# PIC32MX254F128D register map
Vendor: Microchip
Registers are 32-bit, read-write, reset 0x0 unless marked. A register's access mark holds for its fields unless they carry their own. Addresses are absolute, and some are shared; only a register's first bit layout is shown; [hi:lo] are bit positions; {n}, {i} and the like mark numbered series.

## CMP3
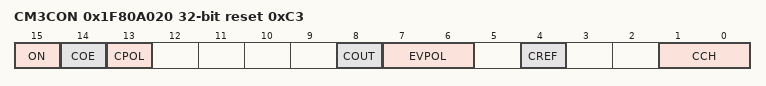
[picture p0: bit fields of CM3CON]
0x1F80A020 CM3CON reset 0xC3
  [15] ON, [14] COE, [13] CPOL, [8] COUT, [7:6] EVPOL, [4] CREF, [1:0] CCH

## cmp_control_pb
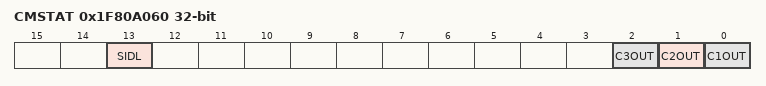
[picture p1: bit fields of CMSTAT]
0x1F80A060 CMSTAT reset not defined — (power-on value ------------------------00---x00)
  [13] SIDL, [2] C3OUT, [1] C2OUT ro, [0] C1OUT ro

## CTMU
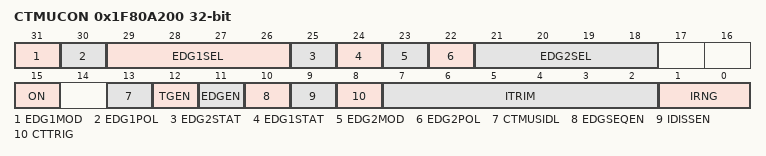
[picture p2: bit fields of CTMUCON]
0x1F80A200 CTMUCON
  [31] EDG1MOD, [30] EDG1POL, [29:26] EDG1SEL, [25] EDG2STAT, [24] EDG1STAT, [23] EDG2MOD, [22] EDG2POL, [21:18] EDG2SEL, [15] ON, [13] CTMUSIDL, [12] TGEN, [11] EDGEN, [10] EDGSEQEN, [9] IDISSEN, [8] CTTRIG, [7:2] ITRIM, [1:0] IRNG

## CRU
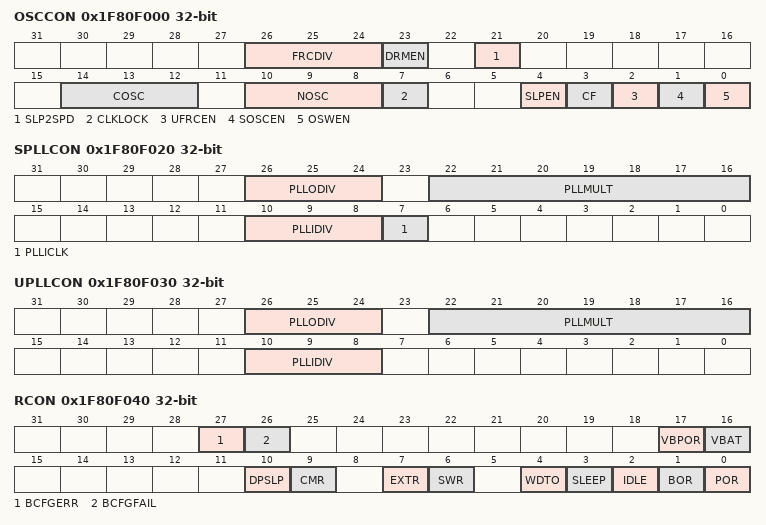
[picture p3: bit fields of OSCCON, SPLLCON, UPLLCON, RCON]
0x1F80F000 OSCCON reset not defined — (power-on value -----0000-x------000-xxx0--000x0)
  [26:24] FRCDIV, [23] DRMEN, [21] SLP2SPD, [14:12] COSC ro, [10:8] NOSC, [7] CLKLOCK, [4] SLPEN, [3] CF, [2] UFRCEN, [1] SOSCEN, [0] OSWEN
0x1F80F010 OSCTUN
  [5:0] TUN
0x1F80F020 SPLLCON reset not defined — (power-on value -----001-xxxxxxx-----xxx0-------)
  [26:24] PLLODIV, [22:16] PLLMULT, [10:8] PLLIDIV, [7] PLLICLK
0x1F80F030 UPLLCON reset not defined — (power-on value -----001-xxxxxxx-----001--------)
  [26:24] PLLODIV, [22:16] PLLMULT, [10:8] PLLIDIV
0x1F80F040 RCON reset not defined — (power-on value ----00---------------x0-00-00011)
  [27] BCFGERR, [26] BCFGFAIL, [17] VBPOR, [16] VBAT, [10] DPSLP, [9] CMR, [7] EXTR, [6] SWR, [4] WDTO, [3] SLEEP, [2] IDLE, [1] BOR, [0] POR
0x1F80F050 RSWRST wo
  [0] SWRST
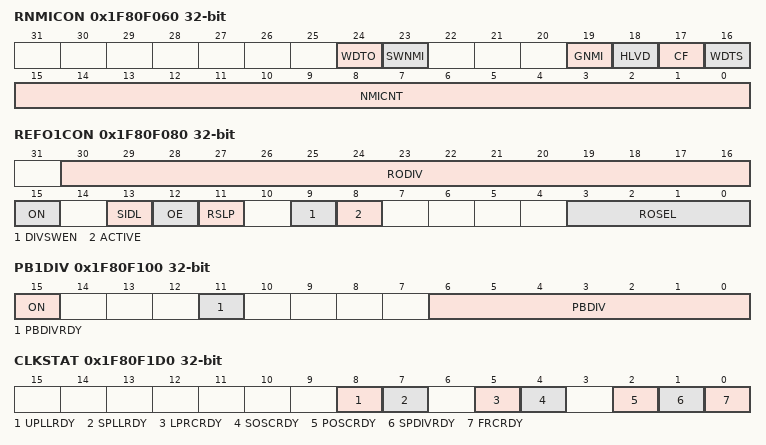
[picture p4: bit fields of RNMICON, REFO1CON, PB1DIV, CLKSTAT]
0x1F80F060 RNMICON
  [24] WDTO, [23] SWNMI, [19] GNMI, [18] HLVD, [17] CF, [16] WDTS, [15:0] NMICNT
0x1F80F070 PWRCON
  [0] VREGS
0x1F80F080 REFO1CON
  [30:16] RODIV, [15] ON, [13] SIDL, [12] OE, [11] RSLP, [9] DIVSWEN, [8] ACTIVE ro, [3:0] ROSEL
0x1F80F090 REFO1TRIM
  [31:23] ROTRIM
0x1F80F100 PB1DIV reset not defined — (power-on value ----------------1---1----xxxxxxx)
  [15] ON, [11] PBDIVRDY ro, [6:0] PBDIV
0x1F80F1D0 CLKSTAT reset not defined — (power-on value ------------------------0-00-0x0)
  [8] UPLLRDY, [7] SPLLRDY ro, [5] LPRCRDY ro, [4] SOSCRDY ro, [2] POSCRDY ro, [1] SPDIVRDY, [0] FRCRDY ro

## CFG
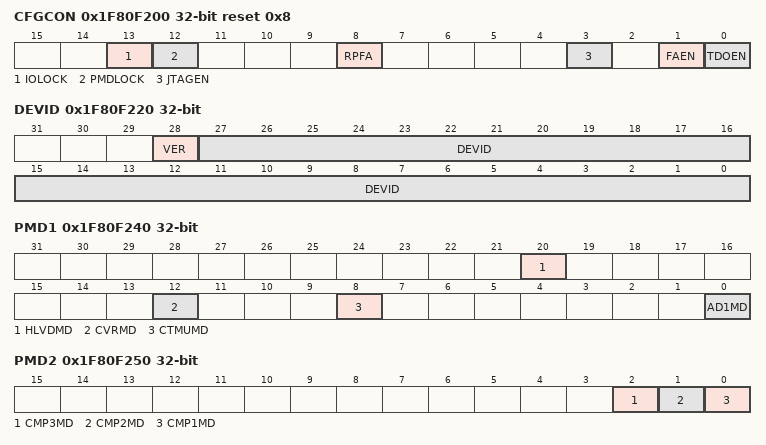
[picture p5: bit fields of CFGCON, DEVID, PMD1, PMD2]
0x1F80F200 CFGCON reset 0x8
  [13] IOLOCK, [12] PMDLOCK, [8] RPFA, [3] JTAGEN, [1] FAEN, [0] TDOEN
0x1F80F220 DEVID ro reset not defined — (power-on value xxxxxxxxxxxxxxxxxxxxxxxxxxxxxxxx)
  [28] VER, [27:0] DEVID
0x1F80F230 SYSKEY ro reset not defined — (power-on value xxxxxxxxxxxxxxxxxxxxxxxxxxxxxxxx)
0x1F80F240 PMD1
  [20] HLVDMD, [12] CVRMD, [8] CTMUMD, [0] AD1MD
0x1F80F250 PMD2
  [2] CMP3MD, [1] CMP2MD, [0] CMP1MD
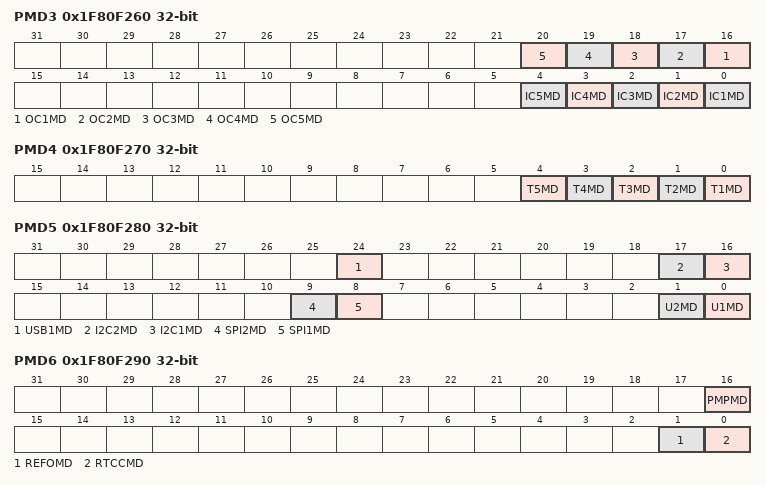
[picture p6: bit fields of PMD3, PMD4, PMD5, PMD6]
0x1F80F260 PMD3
  [n+15] OC{n}MD (n=1..5), [n-1] IC{n}MD (n=1..5)
0x1F80F270 PMD4
  [n-1] T{n}MD (n=1..5)
0x1F80F280 PMD5
  [24] USB1MD, [17] I2C2MD, [16] I2C1MD, [9] SPI2MD, [8] SPI1MD, [1] U2MD, [0] U1MD
0x1F80F290 PMD6
  [16] PMPMD, [1] REFOMD, [0] RTCCMD

## NVM
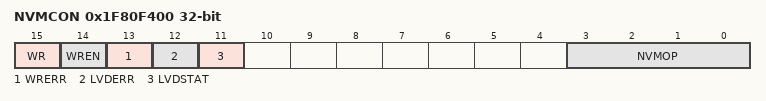
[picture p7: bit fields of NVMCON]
0x1F80F400 NVMCON
  [15] WR, [14] WREN, [13] WRERR, [12] LVDERR, [11] LVDSTAT, [3:0] NVMOP
0x1F80F410 NVMKEY wo
0x1F80F420 NVMADDR
0x1F80F430 NVMDATA
0x1F80F440 NVMSRCADDR

## WDT
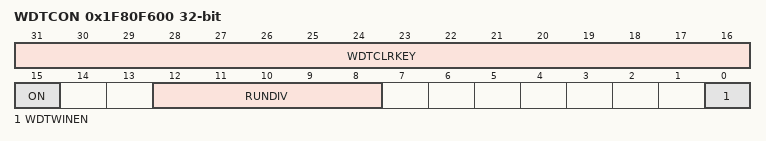
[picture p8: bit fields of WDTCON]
0x1F80F600 WDTCON reset not defined — (power-on value 0000000000000000x--xxxxx-------0)
  [31:16] WDTCLRKEY wo, [15] ON, [12:8] RUNDIV ro, [0] WDTWINEN

## RPINRx
{0x1F80FA00+4i} INT{i}R (i=1..4)
  [3:0] INT{i}R
{0x1F80FA10+4i} T{i}CKR (i=2..5)
  [3:0] T{i}CKR
{0x1F80FA24+4i} IC{i}R (i=1..5)
  [3:0] IC{i}R
0x1F80FA48 OCFAR
  [3:0] OCFAR
0x1F80FA4C OCFBR
  [3:0] OCFBR
0x1F80FA50 U1RXR
  [3:0] U1RXR
0x1F80FA54 U1CTSR
  [3:0] U1CTSR
0x1F80FA58 U2RXR
  [3:0] U2RXR
0x1F80FA5C U2CTSR
  [3:0] U2CTSR
0x1F80FA84 SDI1R
  [3:0] SDI1R
0x1F80FA88 SS1R
  [3:0] SS1R
0x1F80FA90 SDI2R
  [3:0] SDI2R
0x1F80FA94 SS2R
  [3:0] SS2R
0x1F80FAB8 REFCLKIR
  [3:0] REFCLKIR
